# MIMXRT1024 register map
Vendor: nxp.com; File version: 1.0
CPU: CM7 r0p1, little endian, MPU, FPU, VTOR, 4 interrupt priority bits
Registers are 32-bit, read-write, reset 0x0 unless marked. A register's access mark holds for its fields unless they carry their own. Offsets are from the block's base; [hi:lo] are bit positions; {n}, {i} and the like mark numbered series; 'fields as' and 'values as' point back to an identical list.

## ADC1 — Analog-to-Digital Converter
Base 0x400C4000; register names take the prefix ADC1_
Same registers: ADC2 0x400C8000 (register names take the prefix ADC2_)
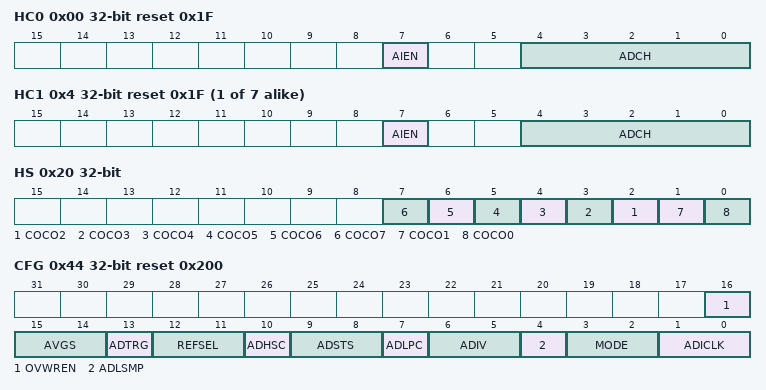
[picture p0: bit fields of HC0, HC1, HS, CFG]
0x00 HC0 reset 0x1F — Control register for hardware triggers
  [7] AIEN — Conversion Complete Interrupt Enable/Disable Control
    0=Conversion complete interrupt disabled; 1=Conversion complete interrupt enabled
  [4:0] ADCH — Input Channel Select
    {v}=External channels 0 to 15 See External Signals for more information (v=0..9); 16=External channel selection from ADC_ETC; 25=VREFSH = internal channel, for ADC self-test, hard connected to VRH internally; 31=Conversion Disabled. Hardware Triggers will not initiate any conversion.
{0x0+4i} HC{i} (i=1..7) reset 0x1F — Control register for hardware triggers
  fields as HC0
0x20 HS ro — Status register for HW triggers
  [n] COCO{n} (n=2..7) — See description for COCO1.
  [1] COCO1 — Conversion Complete Flag
  [0] COCO0 — Conversion Complete Flag
0x24 R0 ro — Data result register for HW triggers
  [11:0] CDATA — Data (result of an ADC conversion)
{0x24+4i} R{i} (i=1..7) ro — Data result register for HW triggers
  [11:0] CDATA — Data (result of an ADC conversion)
0x44 CFG reset 0x200 — Configuration register
  [16] OVWREN — Data Overwrite Enable
    0=Disable the overwriting. Existing Data in Data result register will not be overwritten by subsequent converted data.; 1=Enable the overwriting
  [15:14] AVGS — Hardware Average select
    0=4 samples averaged; 1=8 samples averaged; 2=16 samples averaged; 3=32 samples averaged
  [13] ADTRG — Conversion Trigger Select
    0=Software trigger selected; 1=Hardware trigger selected
  [12:11] REFSEL — Voltage Reference Selection
    0=Selects VREFH/VREFL as reference voltage
  [10] ADHSC — High Speed Configuration
    0=Normal conversion selected; 1=High speed conversion selected
  [9:8] ADSTS — Defines the total sample time duration in number of full cycles
    0=Sample period (ADC clocks) = 3 if ADLSMP=0b Sample period (ADC clocks) = 13 if ADLSMP=1b; 1=Sample period (ADC clocks) = 5 if ADLSMP=0b Sample period (ADC clocks) = 17 if ADLSMP=1b; 2=Sample period (ADC clocks) = 7 if ADLSMP=0b Sample period (ADC clocks) = 21 if ADLSMP=1b; 3=Sample period (ADC clocks) = 9 if ADLSMP=0b Sample period (ADC clocks) = 25 if ADLSMP=1b
  [7] ADLPC — Low-Power Configuration
    0=ADC hard block not in low power mode; 1=ADC hard block in low power mode
  [6:5] ADIV — Clock Divide Select
    0=Input clock; 1=Input clock / 2; 2=Input clock / 4; 3=Input clock / 8
  [4] ADLSMP — Long Sample Time Configuration
    0=Short sample mode; 1=Long sample mode
  [3:2] MODE — Conversion Mode Selection
    0=8-bit conversion; 1=10-bit conversion; 2=12-bit conversion
  [1:0] ADICLK — Input Clock Select
    0=IPG clock; 1=IPG clock divided by 2; 3=Asynchronous clock (ADACK)
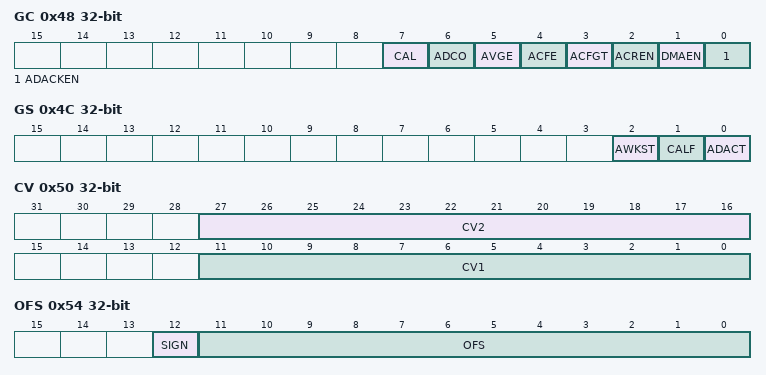
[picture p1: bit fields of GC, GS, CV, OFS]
0x48 GC — General control register
  [7] CAL — Calibration
  [6] ADCO — Continuous Conversion Enable
    0=One conversion or one set of conversions if the hardware average function is enabled (AVGE=1) after initiating a conversion; 1=Continuous conversions or sets of conversions if the hardware average function is enabled (AVGE=1) after initiating a conversion
  [5] AVGE — Hardware average enable
    0=Hardware average function disabled; 1=Hardware average function enabled
  [4] ACFE — Compare Function Enable
    0=Compare function disabled; 1=Compare function enabled
  [3] ACFGT — Compare Function Greater Than Enable
    0=Configures "Less Than Threshold, Outside Range Not Inclusive and Inside Range Not Inclusive" functionality based on the values placed in the ADC_CV register; 1=Configures "Greater Than Or Equal To Threshold, Outside Range Inclusive and Inside Range Inclusive" functionality based on the values placed in the ADC_CV registers
  [2] ACREN — Compare Function Range Enable
    0=Range function disabled. Only the compare value 1 of ADC_CV register (CV1) is compared.; 1=Range function enabled. Both compare values of ADC_CV registers (CV1 and CV2) are compared.
  [1] DMAEN — DMA Enable
    0=DMA disabled (default); 1=DMA enabled
  [0] ADACKEN — Asynchronous clock output enable
    0=Asynchronous clock output disabled; Asynchronous clock only enabled if selected by ADICLK and a conversion is active; 1=Asynchronous clock and clock output enabled regardless of the state of the ADC
0x4C GS — General status register
  [2] AWKST write-1-clears — Asynchronous wakeup interrupt status
    0=No asynchronous interrupt; 1=Asynchronous wake up interrupt occurred in stop mode
  [1] CALF write-1-clears — Calibration Failed Flag
    0=Calibration completed normally; 1=Calibration failed. ADC accuracy specifications are not guaranteed.
  [0] ADACT ro — Conversion Active
    0=Conversion not in progress; 1=Conversion in progress
0x50 CV — Compare value register
  [27:16] CV2 — Compare Value 2
  [11:0] CV1 — Compare Value 1
0x54 OFS — Offset correction value register
  [12] SIGN — Sign bit
    0=The offset value is added with the raw result; 1=The offset value is subtracted from the raw converted value
  [11:0] OFS — Offset value
0x58 CAL — Calibration value register
  [3:0] CAL_CODE — Calibration Result Value
